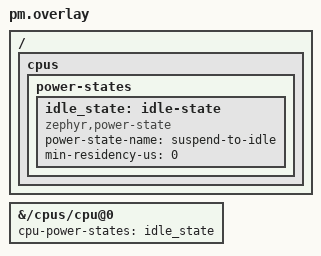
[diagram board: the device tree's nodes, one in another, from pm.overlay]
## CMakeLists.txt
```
# SPDX-License-Identifier: Apache-2.0

cmake_minimum_required(VERSION 3.15.7)
find_package(Zephyr REQUIRED HINTS $ENV{ZEPHYR_BASE})
project(timer_api)

FILE(GLOB app_sources src/*.c)
target_sources(app PRIVATE ${app_sources})
```

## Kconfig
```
# SPDX-License-Identifier: Apache-2.0
# Copyright (c) 2023 Nordic Semiconductor ASA

config SYS_CLOCK_TICKS_PER_SEC
	default 16384 if NRF_RTC_TIMER && TICKLESS_KERNEL

config TEST_PROVIDE_PM_HOOKS
	bool "Provide the PM hooks this test needs"
	select HAS_PM
	select PM_STATE_SET_IRQ_UNLOCKED
	help
	  CONFIG_PM needs HAS_PM, which only SoCs implementing low-power states
	  select. src/pm_hooks.c supplies the two required hooks so the PM idle
	  path can be exercised anywhere.

source "Kconfig.zephyr"
```

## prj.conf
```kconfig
CONFIG_ZTEST=y
CONFIG_TEST_USERSPACE=y

CONFIG_MP_MAX_NUM_CPUS=1
CONFIG_RNG=y
CONFIG_TEST_RANDOM_GENERATOR=y
```

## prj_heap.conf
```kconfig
CONFIG_TIMEOUT_USE_MIN_HEAP=y
```

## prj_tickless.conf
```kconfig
CONFIG_ZTEST=y
CONFIG_PM=y
CONFIG_TICKLESS_KERNEL=y
CONFIG_MP_MAX_NUM_CPUS=1
CONFIG_TEST_RANDOM_GENERATOR=y

CONFIG_TEST_USERSPACE=y
```

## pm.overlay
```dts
/*
 * SPDX-FileCopyrightText: Copyright The Zephyr Project Contributors
 * SPDX-License-Identifier: Apache-2.0
 *
 * Minimal power state so CONFIG_PM has something to enter. The point is to
 * reach sys_clock_idle_enter() and sys_clock_idle_exit(), not to emulate a
 * real low-power mode.
 */

/ {
	cpus {
		power-states {
			idle_state: idle-state {
				compatible = "zephyr,power-state";
				power-state-name = "suspend-to-idle";
				min-residency-us = <0>;
			};
		};
	};
};

&{/cpus/cpu@0} {
	cpu-power-states = <&idle_state>;
};
```

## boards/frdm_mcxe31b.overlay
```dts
/*
 * Copyright 2026 NXP
 *
 * SPDX-License-Identifier: Apache-2.0
 */

/* Select the RTC (rtc_jdp) as the kernel system timer on frdm_mcxe31b. */

/ {
	chosen {
		zephyr,system-timer = &rtc;
	};
};

&rtc {
	/*
	 * prescaler = 1 -> 32 kHz counter rate. The default calendar prescaler
	 * (16384) would give an unusable ~2 Hz tick.
	 */
	prescaler = <1>;
	status = "okay";
};

/*
 * The RTC instance now backs the system tick; it can no longer provide the
 * counter-based RTC calendar on the same hardware.
 */
&counter_rtc {
	status = "disabled";
};
```

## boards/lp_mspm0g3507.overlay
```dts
/*
 * SPDX-FileCopyrightText: Copyright (c) 2026 Linumiz
 *
 * SPDX-License-Identifier: Apache-2.0
 */

/* Enable system timer for this test. */
&timg12 {
	status = "okay";
};
```

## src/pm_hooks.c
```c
/*
 * SPDX-FileCopyrightText: Copyright The Zephyr Project Contributors
 * SPDX-License-Identifier: Apache-2.0
 */

#include <zephyr/kernel.h>

#ifdef CONFIG_TEST_PROVIDE_PM_HOOKS

#include <zephyr/pm/pm.h>

/*
 * CONFIG_PM needs an SoC to implement these two hooks, and only SoCs with real
 * low-power states do. This test wants the PM idle path, not a low-power mode,
 * so pm_state_set() just waits for the next interrupt the way an ordinary idle
 * would. That is enough to reach sys_clock_idle_enter() and, on the way out,
 * sys_clock_idle_exit().
 *
 * k_cpu_idle() returns with interrupts unlocked, hence
 * CONFIG_PM_STATE_SET_IRQ_UNLOCKED in the test configuration.
 */
void pm_state_set(enum pm_state state, uint8_t substate_id)
{
	ARG_UNUSED(state);
	ARG_UNUSED(substate_id);

	k_cpu_idle();
}

void pm_state_exit_post_ops(enum pm_state state, uint8_t substate_id)
{
	ARG_UNUSED(state);
	ARG_UNUSED(substate_id);
}

#endif /* CONFIG_TEST_PROVIDE_PM_HOOKS */
```

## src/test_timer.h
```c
/*
 * Copyright (c) 2016 Intel Corporation
 *
 * SPDX-License-Identifier: Apache-2.0
 */

#ifndef __TEST_TIMER_H__
#define __TEST_TIMER_H__
#include <zephyr/types.h>

struct timer_data {
	int expire_cnt;
	int stop_cnt;
	s64_t timestamp;
};

void test_timer_duration_period(void);
void test_timer_period_0(void);
void test_timer_expirefn_null(void);
void test_timer_periodicity(void);
void test_timer_status_get(void);
void test_timer_status_get_anytime(void);
void test_timer_status_sync(void);
void test_timer_k_define(void);
void test_timer_user_data(void);

#endif /* __TEST_TIMER_H__ */
```

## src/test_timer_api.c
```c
/*
 * Copyright (c) 2016 Intel Corporation
 *
 * SPDX-License-Identifier: Apache-2.0
 */

#include "test_timer.h"
#include <ztest.h>

#define DURATION 100
#define PERIOD 50
#define EXPIRE_TIMES 4
#define WITHIN_ERROR(var, target, epsilon)       \
		(((var) >= (target)) && ((var) <= (target) + (epsilon)))

static void duration_expire(struct k_timer *timer);
static void duration_stop(struct k_timer *timer);

/** TESTPOINT: init timer via K_TIMER_DEFINE */
K_TIMER_DEFINE(ktimer, duration_expire, duration_stop);
static struct k_timer timer;
static struct timer_data tdata;

#define TIMER_ASSERT(exp, tmr)			 \
	do {					 \
		if (!(exp)) {			 \
			k_timer_stop(tmr);	 \
			zassert_true(exp, NULL); \
		}				 \
	} while (0)

static void init_timer_data(void)
{
	tdata.expire_cnt = 0;
	tdata.stop_cnt = 0;
}

/* entry routines */
static void duration_expire(struct k_timer *timer)
{
	/** TESTPOINT: expire function */
	tdata.expire_cnt++;
	if (tdata.expire_cnt == 1) {
		TIMER_ASSERT(k_uptime_delta(&tdata.timestamp) >= DURATION,
			     timer);
	} else {
		TIMER_ASSERT(k_uptime_delta(&tdata.timestamp) >= PERIOD, timer);
	}

	tdata.timestamp = k_uptime_get();
	if (tdata.expire_cnt >= EXPIRE_TIMES) {
		k_timer_stop(timer);
	}
}

static void duration_stop(struct k_timer *timer)
{
	tdata.stop_cnt++;
}

static void period0_expire(struct k_timer *timer)
{
	tdata.expire_cnt++;
}

static void status_expire(struct k_timer *timer)
{
	/** TESTPOINT: status get upon timer expired */
	TIMER_ASSERT(k_timer_status_get(timer) == 1, timer);
	/** TESTPOINT: remaining get upon timer expired */
	TIMER_ASSERT(k_timer_remaining_get(timer) >= PERIOD, timer);

	if (tdata.expire_cnt >= EXPIRE_TIMES) {
		k_timer_stop(timer);
	}
}

static void busy_wait_ms(s32_t ms)
{
	k_busy_wait(ms*1000);
}

static void status_stop(struct k_timer *timer)
{
	/** TESTPOINT: remaining get upon timer stopped */
	TIMER_ASSERT(k_timer_remaining_get(timer) == 0, timer);
}

/* test cases */
void test_timer_duration_period(void)
{
	init_timer_data();
	/** TESTPOINT: init timer via k_timer_init */
	k_timer_init(&timer, duration_expire, duration_stop);
	k_timer_start(&timer, DURATION, PERIOD);
	tdata.timestamp = k_uptime_get();
	busy_wait_ms(DURATION + PERIOD * EXPIRE_TIMES + PERIOD / 2);
	/** TESTPOINT: check expire and stop times */
	TIMER_ASSERT(tdata.expire_cnt == EXPIRE_TIMES, &timer);
	TIMER_ASSERT(tdata.stop_cnt == 1, &timer);

	/* cleanup environemtn */
	k_timer_stop(&timer);
}

void test_timer_period_0(void)
{
	init_timer_data();
	/** TESTPOINT: set period 0 */
	k_timer_init(&timer, period0_expire, NULL);
	k_timer_start(&timer, DURATION, 0);
	tdata.timestamp = k_uptime_get();
	busy_wait_ms(DURATION + 1);

	/** TESTPOINT: ensure it is one-short timer */
	TIMER_ASSERT(tdata.expire_cnt == 1, &timer);
	TIMER_ASSERT(tdata.stop_cnt == 0, &timer);

	/* cleanup environemtn */
	k_timer_stop(&timer);
}

void test_timer_expirefn_null(void)
{
	init_timer_data();
	/** TESTPOINT: expire function NULL */
	k_timer_init(&timer, NULL, duration_stop);
	k_timer_start(&timer, DURATION, PERIOD);
	busy_wait_ms(DURATION + PERIOD * EXPIRE_TIMES + PERIOD / 2);

	k_timer_stop(&timer);
	/** TESTPOINT: expire handler is not invoked */
	TIMER_ASSERT(tdata.expire_cnt == 0, &timer);
	/** TESTPOINT: stop handler is invoked */
	TIMER_ASSERT(tdata.stop_cnt == 1, &timer);

	/* cleanup environment */
	k_timer_stop(&timer);
}

void test_timer_periodicity(void)
{
	s64_t delta;

	init_timer_data();
	/** TESTPOINT: set duration 0 */
	k_timer_init(&timer, NULL, NULL);
	k_timer_start(&timer, 0, PERIOD);

	/* clear the expiration that would have happenned due to
	 * whatever duration that was set.
	 */
	k_timer_status_sync(&timer);
	tdata.timestamp = k_uptime_get();

	for (int i = 0; i < EXPIRE_TIMES; i++) {
		/** TESTPOINT: expired times returned by status sync */
		TIMER_ASSERT(k_timer_status_sync(&timer) == 1, &timer);

		delta = k_uptime_delta(&tdata.timestamp);

		/** TESTPOINT: check if timer fired within 1ms of the
		 *  expected period (firing time)
		 */
		TIMER_ASSERT(WITHIN_ERROR(delta, PERIOD, 1), &timer);
	}

	/* cleanup environment */
	k_timer_stop(&timer);
}

void test_timer_status_get(void)
{
	init_timer_data();
	k_timer_init(&timer, status_expire, status_stop);
	k_timer_start(&timer, DURATION, PERIOD);
	/** TESTPOINT: status get upon timer starts */
	TIMER_ASSERT(k_timer_status_get(&timer) == 0, &timer);
	/** TESTPOINT: remaining get upon timer starts */
	TIMER_ASSERT(k_timer_remaining_get(&timer) >= DURATION / 2, &timer);

	/* cleanup environment */
	k_timer_stop(&timer);
}

void test_timer_status_get_anytime(void)
{
	init_timer_data();
	k_timer_init(&timer, NULL, NULL);
	k_timer_start(&timer, DURATION, PERIOD);
	busy_wait_ms(DURATION + PERIOD * (EXPIRE_TIMES - 1) + PERIOD / 2);

	/** TESTPOINT: status get at any time */
	TIMER_ASSERT(k_timer_status_get(&timer) == EXPIRE_TIMES, &timer);

	/* cleanup environment */
	k_timer_stop(&timer);
}

void test_timer_status_sync(void)
{
	init_timer_data();
	k_timer_init(&timer, duration_expire, duration_stop);
	k_timer_start(&timer, DURATION, PERIOD);

	for (int i = 0; i < EXPIRE_TIMES; i++) {
		/** TESTPOINT: check timer not expire */
		TIMER_ASSERT(tdata.expire_cnt == i, &timer);
		/** TESTPOINT： expired times returned by status sync */
		TIMER_ASSERT(k_timer_status_sync(&timer) == 1, &timer);
		/** TESTPOINT: check timer not expire */
		TIMER_ASSERT(tdata.expire_cnt == (i + 1), &timer);
	}

	/* cleanup environment */
	k_timer_stop(&timer);
}

void test_timer_k_define(void)
{
	init_timer_data();
	/** TESTPOINT: init timer via k_timer_init */
	k_timer_start(&ktimer, DURATION, PERIOD);
	tdata.timestamp = k_uptime_get();
	busy_wait_ms(DURATION + PERIOD * EXPIRE_TIMES + PERIOD / 2);

	/** TESTPOINT: check expire and stop times */
	TIMER_ASSERT(tdata.expire_cnt == EXPIRE_TIMES, &ktimer);
	TIMER_ASSERT(tdata.stop_cnt == 1, &ktimer);

	/* cleanup environment */
	k_timer_stop(&ktimer);
}

/* k_timer_user_data_set/get test */

static void user_data_timer_handler(struct k_timer *timer);

K_TIMER_DEFINE(timer0, user_data_timer_handler, NULL);
K_TIMER_DEFINE(timer1, user_data_timer_handler, NULL);
K_TIMER_DEFINE(timer2, user_data_timer_handler, NULL);
K_TIMER_DEFINE(timer3, user_data_timer_handler, NULL);
K_TIMER_DEFINE(timer4, user_data_timer_handler, NULL);

static struct k_timer *user_data_timer[5] = {
	&timer0, &timer1, &timer2, &timer3, &timer4
};

static const intptr_t user_data[5] = { 0x1337, 0xbabe, 0xd00d, 0xdeaf, 0xfade };

static int user_data_correct[5] = { 0, 0, 0, 0, 0 };

static void user_data_timer_handler(struct k_timer *timer)
{
	int timer_num = timer == user_data_timer[0] ? 0 :
			timer == user_data_timer[1] ? 1 :
			timer == user_data_timer[2] ? 2 :
			timer == user_data_timer[3] ? 3 :
			timer == user_data_timer[4] ? 4 : -1;

	if (timer_num == -1) {
		return;
	}

	intptr_t data_retrieved = (intptr_t)k_timer_user_data_get(timer);
	user_data_correct[timer_num] = user_data[timer_num] == data_retrieved;
}

void test_timer_user_data(void)
{
	int ii;

	for (ii = 0; ii < 5; ii++) {
		intptr_t check;

		k_timer_user_data_set(user_data_timer[ii],
				      (void *)user_data[ii]);
		check = (intptr_t)k_timer_user_data_get(user_data_timer[ii]);

		zassert_true(check == user_data[ii], NULL);
	}

	for (ii = 0; ii < 5; ii++) {
		k_timer_start(user_data_timer[ii], 50 + ii * 50, 0);
	}

	k_sleep(50 * ii + 50);

	for (ii = 0; ii < 5; ii++) {
		k_timer_stop(user_data_timer[ii]);
	}

	for (ii = 0; ii < 5; ii++) {
		zassert_true(user_data_correct[ii], NULL);
	}
}
```

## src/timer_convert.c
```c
/*
 * Copyright (c) 2019 Intel Corporation
 *
 * SPDX-License-Identifier: Apache-2.0
 */
#include <zephyr/ztest.h>
#include <zephyr/types.h>
#include <zephyr/sys/time_units.h>
#include <zephyr/sys/printk.h>
#include <zephyr/random/random.h>

#define NUM_RANDOM 100

enum units { UNIT_ticks, UNIT_cyc, UNIT_ms, UNIT_us, UNIT_ns };

enum round { ROUND_floor, ROUND_ceil, ROUND_near };

static const char *const round_s[] __maybe_unused = {
	[ROUND_floor] = "floor",
	[ROUND_ceil] = "ceil",
	[ROUND_near] = "near",
};

static const char *const unit_s[] = {
	[UNIT_ticks] = "ticks",
	[UNIT_cyc] = "cyc",
	[UNIT_ms] = "ms",
	[UNIT_us] = "us",
	[UNIT_ns] = "ns",
};

struct test_rec {
	enum units src;
	enum units dst;
	int precision; /* 32 or 64 */
	enum round round;
	void *func;
};

#define TESTREC(src, dst, round, prec) { \
		UNIT_##src, UNIT_##dst, prec, ROUND_##round,		\
			(void *)test_##src##_to_##dst##_##round##prec	\
	}								\

#if defined(CONFIG_TIMER_READS_ITS_FREQUENCY_AT_RUNTIME) || \
	defined(CONFIG_SYSTEM_CLOCK_HW_CYCLES_PER_SEC_RUNTIME_UPDATE)
#define TESTVAR(src, dst, round, prec)
#else
#define TESTVAR(src, dst, round, prec)					\
	uint##prec##_t test_##src##_to_##dst##_##round##prec##_val =	\
		k_##src##_to_##dst##_##round##prec(42);
#endif

#define TESTFUNC(src, dst, round, prec)					\
	TESTVAR(src, dst, round, prec)					\
	static uint##prec##_t test_##src##_to_##dst##_##round##prec(uint##prec##_t t) { \
		return k_##src##_to_##dst##_##round##prec(t);		\
	}

TESTFUNC(ms, cyc, floor, 32)
TESTFUNC(ms, cyc, floor, 64)
TESTFUNC(ms, cyc, near, 32)
TESTFUNC(ms, cyc, near, 64)
TESTFUNC(ms, cyc, ceil, 32)
TESTFUNC(ms, cyc, ceil, 64)
TESTFUNC(ms, ticks, floor, 32)
TESTFUNC(ms, ticks, floor, 64)
TESTFUNC(ms, ticks, near, 32)
TESTFUNC(ms, ticks, near, 64)
TESTFUNC(ms, ticks, ceil, 32)
TESTFUNC(ms, ticks, ceil, 64)
TESTFUNC(us, cyc, floor, 32)
TESTFUNC(us, cyc, floor, 64)
TESTFUNC(us, cyc, near, 32)
TESTFUNC(us, cyc, near, 64)
TESTFUNC(us, cyc, ceil, 32)
TESTFUNC(us, cyc, ceil, 64)
TESTFUNC(us, ticks, floor, 32)
TESTFUNC(us, ticks, floor, 64)
TESTFUNC(us, ticks, near, 32)
TESTFUNC(us, ticks, near, 64)
TESTFUNC(us, ticks, ceil, 32)
TESTFUNC(us, ticks, ceil, 64)
TESTFUNC(cyc, ms, floor, 32)
TESTFUNC(cyc, ms, floor, 64)
TESTFUNC(cyc, ms, near, 32)
TESTFUNC(cyc, ms, near, 64)
TESTFUNC(cyc, ms, ceil, 32)
TESTFUNC(cyc, ms, ceil, 64)
TESTFUNC(cyc, us, floor, 32)
TESTFUNC(cyc, us, floor, 64)
TESTFUNC(cyc, us, near, 32)
TESTFUNC(cyc, us, near, 64)
TESTFUNC(cyc, us, ceil, 32)
TESTFUNC(cyc, us, ceil, 64)
TESTFUNC(cyc, ticks, floor, 32)
TESTFUNC(cyc, ticks, floor, 64)
TESTFUNC(cyc, ticks, near, 32)
TESTFUNC(cyc, ticks, near, 64)
TESTFUNC(cyc, ticks, ceil, 32)
TESTFUNC(cyc, ticks, ceil, 64)
TESTFUNC(ticks, ms, floor, 32)
TESTFUNC(ticks, ms, floor, 64)
TESTFUNC(ticks, ms, near, 32)
TESTFUNC(ticks, ms, near, 64)
TESTFUNC(ticks, ms, ceil, 32)
TESTFUNC(ticks, ms, ceil, 64)
TESTFUNC(ticks, us, floor, 32)
TESTFUNC(ticks, us, floor, 64)
TESTFUNC(ticks, us, near, 32)
TESTFUNC(ticks, us, near, 64)
TESTFUNC(ticks, us, ceil, 32)
TESTFUNC(ticks, us, ceil, 64)
TESTFUNC(ticks, cyc, floor, 32)
TESTFUNC(ticks, cyc, floor, 64)
TESTFUNC(ticks, cyc, near, 32)
TESTFUNC(ticks, cyc, near, 64)
TESTFUNC(ticks, cyc, ceil, 32)
TESTFUNC(ticks, cyc, ceil, 64)
TESTFUNC(ns, cyc, floor, 32)
TESTFUNC(ns, cyc, floor, 64)
TESTFUNC(ns, cyc, near, 32)
TESTFUNC(ns, cyc, near, 64)
TESTFUNC(ns, cyc, ceil, 32)
TESTFUNC(ns, cyc, ceil, 64)
TESTFUNC(ns, ticks, floor, 32)
TESTFUNC(ns, ticks, floor, 64)
TESTFUNC(ns, ticks, near, 32)
TESTFUNC(ns, ticks, near, 64)
TESTFUNC(ns, ticks, ceil, 32)
TESTFUNC(ns, ticks, ceil, 64)
TESTFUNC(cyc, ns, floor, 32)
TESTFUNC(cyc, ns, floor, 64)
TESTFUNC(cyc, ns, near, 32)
TESTFUNC(cyc, ns, near, 64)
TESTFUNC(cyc, ns, ceil, 32)
TESTFUNC(cyc, ns, ceil, 64)
TESTFUNC(ticks, ns, floor, 32)
TESTFUNC(ticks, ns, floor, 64)
TESTFUNC(ticks, ns, near, 32)
TESTFUNC(ticks, ns, near, 64)
TESTFUNC(ticks, ns, ceil, 32)
TESTFUNC(ticks, ns, ceil, 64)

static struct test_rec tests[] = {
	 TESTREC(ms, cyc, floor, 32),
	 TESTREC(ms, cyc, floor, 64),
	 TESTREC(ms, cyc, near, 32),
	 TESTREC(ms, cyc, near, 64),
	 TESTREC(ms, cyc, ceil, 32),
	 TESTREC(ms, cyc, ceil, 64),
	 TESTREC(ms, ticks, floor, 32),
	 TESTREC(ms, ticks, floor, 64),
	 TESTREC(ms, ticks, near, 32),
	 TESTREC(ms, ticks, near, 64),
	 TESTREC(ms, ticks, ceil, 32),
	 TESTREC(ms, ticks, ceil, 64),
	 TESTREC(us, cyc, floor, 32),
	 TESTREC(us, cyc, floor, 64),
	 TESTREC(us, cyc, near, 32),
	 TESTREC(us, cyc, near, 64),
	 TESTREC(us, cyc, ceil, 32),
	 TESTREC(us, cyc, ceil, 64),
	 TESTREC(us, ticks, floor, 32),
	 TESTREC(us, ticks, floor, 64),
	 TESTREC(us, ticks, near, 32),
	 TESTREC(us, ticks, near, 64),
	 TESTREC(us, ticks, ceil, 32),
	 TESTREC(us, ticks, ceil, 64),
	 TESTREC(cyc, ms, floor, 32),
	 TESTREC(cyc, ms, floor, 64),
	 TESTREC(cyc, ms, near, 32),
	 TESTREC(cyc, ms, near, 64),
	 TESTREC(cyc, ms, ceil, 32),
	 TESTREC(cyc, ms, ceil, 64),
	 TESTREC(cyc, us, floor, 32),
	 TESTREC(cyc, us, floor, 64),
	 TESTREC(cyc, us, near, 32),
	 TESTREC(cyc, us, near, 64),
	 TESTREC(cyc, us, ceil, 32),
	 TESTREC(cyc, us, ceil, 64),
	 TESTREC(cyc, ticks, floor, 32),
	 TESTREC(cyc, ticks, floor, 64),
	 TESTREC(cyc, ticks, near, 32),
	 TESTREC(cyc, ticks, near, 64),
	 TESTREC(cyc, ticks, ceil, 32),
	 TESTREC(cyc, ticks, ceil, 64),
	 TESTREC(ticks, ms, floor, 32),
	 TESTREC(ticks, ms, floor, 64),
	 TESTREC(ticks, ms, near, 32),
	 TESTREC(ticks, ms, near, 64),
	 TESTREC(ticks, ms, ceil, 32),
	 TESTREC(ticks, ms, ceil, 64),
	 TESTREC(ticks, us, floor, 32),
	 TESTREC(ticks, us, floor, 64),
	 TESTREC(ticks, us, near, 32),
	 TESTREC(ticks, us, near, 64),
	 TESTREC(ticks, us, ceil, 32),
	 TESTREC(ticks, us, ceil, 64),
	 TESTREC(ticks, cyc, floor, 32),
	 TESTREC(ticks, cyc, floor, 64),
	 TESTREC(ticks, cyc, near, 32),
	 TESTREC(ticks, cyc, near, 64),
	 TESTREC(ticks, cyc, ceil, 32),
	 TESTREC(ticks, cyc, ceil, 64),
	 TESTREC(ns, cyc, floor, 32),
	 TESTREC(ns, cyc, floor, 64),
	 TESTREC(ns, cyc, near, 32),
	 TESTREC(ns, cyc, near, 64),
	 TESTREC(ns, cyc, ceil, 32),
	 TESTREC(ns, cyc, ceil, 64),
	 TESTREC(ns, ticks, floor, 32),
	 TESTREC(ns, ticks, floor, 64),
	 TESTREC(ns, ticks, near, 32),
	 TESTREC(ns, ticks, near, 64),
	 TESTREC(ns, ticks, ceil, 32),
	 TESTREC(ns, ticks, ceil, 64),
	 TESTREC(cyc, ns, floor, 32),
	 TESTREC(cyc, ns, floor, 64),
	 TESTREC(cyc, ns, near, 32),
	 TESTREC(cyc, ns, near, 64),
	 TESTREC(cyc, ns, ceil, 32),
	 TESTREC(cyc, ns, ceil, 64),
	 TESTREC(ticks, ns, floor, 32),
	 TESTREC(ticks, ns, floor, 64),
	 TESTREC(ticks, ns, near, 32),
	 TESTREC(ticks, ns, near, 64),
	 TESTREC(ticks, ns, ceil, 32),
	 TESTREC(ticks, ns, ceil, 64),
	};

uint32_t get_hz(enum units u)
{
	if (u == UNIT_ticks) {
		return CONFIG_SYS_CLOCK_TICKS_PER_SEC;
	} else if (u == UNIT_cyc) {
		return sys_clock_hw_cycles_per_sec();
	} else if (u == UNIT_ms) {
		return 1000;
	} else if (u == UNIT_us) {
		return 1000000;
	} else if (u == UNIT_ns) {
		return 1000000000;
	}
	__ASSERT(0, "");
	return 0;
}

static void test_conversion(const struct test_rec *t, uint64_t val)
{
	uint32_t from_hz = get_hz(t->src), to_hz = get_hz(t->dst);
	uint64_t result;

	if (t->precision == 32) {
		uint32_t (*convert)(uint32_t) = (uint32_t (*)(uint32_t)) t->func;

		result = convert((uint32_t) val);

		/* If the input value legitimately overflows, then
		 * there is nothing to test
		 */
		if ((val * to_hz) >= ((((uint64_t)from_hz) << 32))) {
			return;
		}
	} else {
		uint64_t (*convert)(uint64_t) = (uint64_t (*)(uint64_t)) t->func;

		result = convert(val);
	}

	/* We expect the ideal result to be equal to "val * to_hz /
	 * from_hz", but that division is the source of precision
	 * issues.  So reexpress our equation as:
	 *
	 *    val * to_hz ==? result * from_hz
	 *              0 ==? val * to_hz - result * from_hz
	 *
	 * The difference is allowed to be in the range [0:from_hz) if
	 * we are rounding down, from (-from_hz:0] if we are rounding
	 * up, or [-from_hz/2:from_hz/2] if we are rounding to the
	 * nearest.
	 */
	int64_t diff = (int64_t)(val * to_hz - result * from_hz);
	int64_t maxdiff, mindiff;

	if (t->round == ROUND_floor) {
		maxdiff = from_hz - 1;
		mindiff = 0;
	} else if (t->round == ROUND_ceil) {
		maxdiff = 0;
		mindiff = -(int64_t)(from_hz-1);
	} else {
		maxdiff = from_hz/2;
		mindiff = -(int64_t)(from_hz/2);
	}

	zassert_true(diff <= maxdiff && diff >= mindiff,
		     "Convert %llu (%llx) from %u Hz to %u Hz %u-bit %s\n"
		     "result %llu (%llx) diff %lld (%llx) should be in [%lld:%lld]",
		     val, val, from_hz, to_hz, t->precision, round_s[t->round],
		     result, result, diff, diff, mindiff, maxdiff);
}

/* Human-readable per-case label, e.g. "ms_to_cyc_floor32". */
static const char *conversion_name(size_t index, const void *value)
{
	const struct test_rec *t = value;
	static char buf[32];

	ARG_UNUSED(index);
	snprintk(buf, sizeof(buf), "%s_to_%s_%s%d",
		 unit_s[t->src], unit_s[t->dst], round_s[t->round], t->precision);
	return buf;
}

static const struct ztest_param_values conversion_vals = {
	.values = tests,
	.count = ARRAY_SIZE(tests),
	.elem_size = sizeof(tests[0]),
	.name_cb = conversion_name,
};

/**
 * @brief Test conversion between time units
 *
 * @details Exercise the kernel time-unit conversion routines over a large set
 * of source/target frequencies, bit widths and rounding modes, converting
 * values between milliseconds, microseconds, nanoseconds, system ticks and
 * hardware cycles and verifying each result is within the rounding-mode bound.
 *
 * @ingroup kernel_timer_tests
 * @verifies ZEP-SRS-28-7
 */
ZTEST_P(timer_api, test_time_conversions)
{
	const struct test_rec *t = ZTEST_GET_PARAM_PTR(struct test_rec);

	test_conversion(t, 0);
	test_conversion(t, 1);
	test_conversion(t, 0x7fffffff);
	test_conversion(t, 0x80000000);
	test_conversion(t, 0xfffffff0);
	if (t->precision == 64) {
		test_conversion(t, 0xffffffff);
		test_conversion(t, 0x100000000ULL);
	}

	for (int j = 0; j < NUM_RANDOM; j++) {
		test_conversion(t, sys_rand32_get());
	}
}

ZTEST_INSTANTIATE_TEST_SUITE_P(conversions, timer_api, test_time_conversions,
			       conversion_vals);
```
